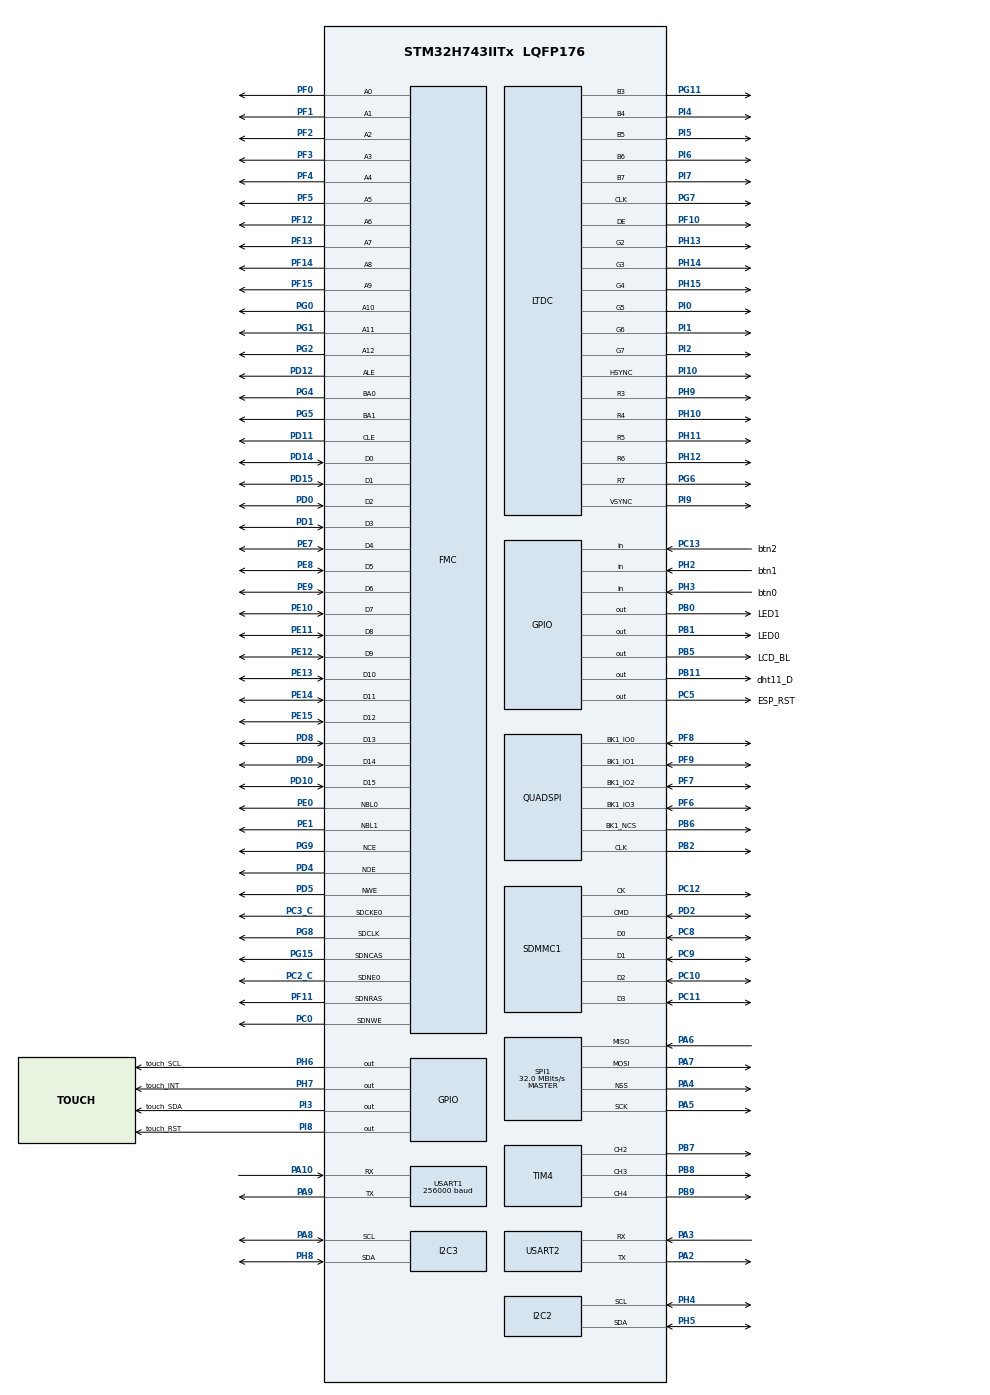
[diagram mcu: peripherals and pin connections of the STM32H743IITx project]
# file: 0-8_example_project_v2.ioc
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CORTEX_M7.CPU_DCache=Disabled
CORTEX_M7.CPU_ICache=Disabled
CORTEX_M7.MPU_Control=__NULL
CORTEX_M7.default_mode_Activation=0
DMA2D.ColorMode=DMA2D_OUTPUT_RGB565
Dma.I2C2_RX.4.Direction=DMA_PERIPH_TO_MEMORY
Dma.I2C2_RX.4.EventEnable=DISABLE
Dma.I2C2_RX.4.FIFOMode=DMA_FIFOMODE_DISABLE
Dma.I2C2_RX.4.Instance=DMA1_Stream4
Dma.I2C2_RX.4.MemDataAlignment=DMA_MDATAALIGN_BYTE
Dma.I2C2_RX.4.MemInc=DMA_MINC_ENABLE
Dma.I2C2_RX.4.Mode=DMA_NORMAL
Dma.I2C2_RX.4.PeriphDataAlignment=DMA_PDATAALIGN_BYTE
Dma.I2C2_RX.4.PeriphInc=DMA_PINC_DISABLE
Dma.I2C2_RX.4.Polarity=HAL_DMAMUX_REQ_GEN_RISING
Dma.I2C2_RX.4.Priority=DMA_PRIORITY_LOW
Dma.I2C2_RX.4.RequestNumber=1
Dma.I2C2_RX.4.SignalID=NONE
Dma.I2C2_RX.4.SyncEnable=DISABLE
Dma.I2C2_RX.4.SyncPolarity=HAL_DMAMUX_SYNC_NO_EVENT
Dma.I2C2_RX.4.SyncRequestNumber=1
Dma.I2C2_RX.4.SyncSignalID=NONE
Dma.I2C2_TX.5.Direction=DMA_MEMORY_TO_PERIPH
Dma.I2C2_TX.5.EventEnable=DISABLE
Dma.I2C2_TX.5.FIFOMode=DMA_FIFOMODE_DISABLE
Dma.I2C2_TX.5.Instance=DMA1_Stream5
Dma.I2C2_TX.5.MemDataAlignment=DMA_MDATAALIGN_BYTE
Dma.I2C2_TX.5.MemInc=DMA_MINC_ENABLE
Dma.I2C2_TX.5.Mode=DMA_NORMAL
Dma.I2C2_TX.5.PeriphDataAlignment=DMA_PDATAALIGN_BYTE
Dma.I2C2_TX.5.PeriphInc=DMA_PINC_DISABLE
Dma.I2C2_TX.5.Polarity=HAL_DMAMUX_REQ_GEN_RISING
Dma.I2C2_TX.5.Priority=DMA_PRIORITY_LOW
Dma.I2C2_TX.5.RequestNumber=1
Dma.I2C2_TX.5.SignalID=NONE
Dma.I2C2_TX.5.SyncEnable=DISABLE
Dma.I2C2_TX.5.SyncPolarity=HAL_DMAMUX_SYNC_NO_EVENT
Dma.I2C2_TX.5.SyncRequestNumber=1
Dma.I2C2_TX.5.SyncSignalID=NONE
Dma.I2C3_RX.6.Direction=DMA_PERIPH_TO_MEMORY
Dma.I2C3_RX.6.EventEnable=DISABLE
Dma.I2C3_RX.6.FIFOMode=DMA_FIFOMODE_DISABLE
Dma.I2C3_RX.6.Instance=DMA1_Stream6
Dma.I2C3_RX.6.MemDataAlignment=DMA_MDATAALIGN_BYTE
Dma.I2C3_RX.6.MemInc=DMA_MINC_ENABLE
Dma.I2C3_RX.6.Mode=DMA_NORMAL
Dma.I2C3_RX.6.PeriphDataAlignment=DMA_PDATAALIGN_BYTE
Dma.I2C3_RX.6.PeriphInc=DMA_PINC_DISABLE
Dma.I2C3_RX.6.Polarity=HAL_DMAMUX_REQ_GEN_RISING
Dma.I2C3_RX.6.Priority=DMA_PRIORITY_LOW
Dma.I2C3_RX.6.RequestNumber=1
Dma.I2C3_RX.6.SignalID=NONE
Dma.I2C3_RX.6.SyncEnable=DISABLE
Dma.I2C3_RX.6.SyncPolarity=HAL_DMAMUX_SYNC_NO_EVENT
Dma.I2C3_RX.6.SyncRequestNumber=1
Dma.I2C3_RX.6.SyncSignalID=NONE
Dma.I2C3_TX.7.Direction=DMA_MEMORY_TO_PERIPH
Dma.I2C3_TX.7.EventEnable=DISABLE
Dma.I2C3_TX.7.FIFOMode=DMA_FIFOMODE_DISABLE
Dma.I2C3_TX.7.Instance=DMA1_Stream7
Dma.I2C3_TX.7.MemDataAlignment=DMA_MDATAALIGN_BYTE
Dma.I2C3_TX.7.MemInc=DMA_MINC_ENABLE
Dma.I2C3_TX.7.Mode=DMA_NORMAL
Dma.I2C3_TX.7.PeriphDataAlignment=DMA_PDATAALIGN_BYTE
Dma.I2C3_TX.7.PeriphInc=DMA_PINC_DISABLE
Dma.I2C3_TX.7.Polarity=HAL_DMAMUX_REQ_GEN_RISING
Dma.I2C3_TX.7.Priority=DMA_PRIORITY_LOW
Dma.I2C3_TX.7.RequestNumber=1
Dma.I2C3_TX.7.SignalID=NONE
Dma.I2C3_TX.7.SyncEnable=DISABLE
Dma.I2C3_TX.7.SyncPolarity=HAL_DMAMUX_SYNC_NO_EVENT
Dma.I2C3_TX.7.SyncRequestNumber=1
Dma.I2C3_TX.7.SyncSignalID=NONE
Dma.Request0=USART1_RX
Dma.Request1=USART1_TX
Dma.Request2=USART2_RX
Dma.Request3=USART2_TX
Dma.Request4=I2C2_RX
Dma.Request5=I2C2_TX
Dma.Request6=I2C3_RX
Dma.Request7=I2C3_TX
Dma.USART1_RX.0.Direction=DMA_PERIPH_TO_MEMORY
Dma.USART1_RX.0.EventEnable=DISABLE
Dma.USART1_RX.0.FIFOMode=DMA_FIFOMODE_DISABLE
Dma.USART1_RX.0.Instance=DMA1_Stream0
Dma.USART1_RX.0.MemDataAlignment=DMA_MDATAALIGN_BYTE
Dma.USART1_RX.0.MemInc=DMA_MINC_ENABLE
Dma.USART1_RX.0.Mode=DMA_CIRCULAR
Dma.USART1_RX.0.PeriphDataAlignment=DMA_PDATAALIGN_BYTE
Dma.USART1_RX.0.PeriphInc=DMA_PINC_DISABLE
Dma.USART1_RX.0.Polarity=HAL_DMAMUX_REQ_GEN_RISING
Dma.USART1_RX.0.Priority=DMA_PRIORITY_LOW
Dma.USART1_RX.0.RequestNumber=1
Dma.USART1_RX.0.SignalID=NONE
Dma.USART1_RX.0.SyncEnable=DISABLE
Dma.USART1_RX.0.SyncPolarity=HAL_DMAMUX_SYNC_NO_EVENT
Dma.USART1_RX.0.SyncRequestNumber=1
Dma.USART1_RX.0.SyncSignalID=NONE
Dma.USART1_TX.1.Direction=DMA_MEMORY_TO_PERIPH
Dma.USART1_TX.1.EventEnable=DISABLE
Dma.USART1_TX.1.FIFOMode=DMA_FIFOMODE_DISABLE
Dma.USART1_TX.1.Instance=DMA1_Stream1
Dma.USART1_TX.1.MemDataAlignment=DMA_MDATAALIGN_BYTE
Dma.USART1_TX.1.MemInc=DMA_MINC_ENABLE
Dma.USART1_TX.1.Mode=DMA_NORMAL
Dma.USART1_TX.1.PeriphDataAlignment=DMA_PDATAALIGN_BYTE
Dma.USART1_TX.1.PeriphInc=DMA_PINC_DISABLE
Dma.USART1_TX.1.Polarity=HAL_DMAMUX_REQ_GEN_RISING
Dma.USART1_TX.1.Priority=DMA_PRIORITY_LOW
Dma.USART1_TX.1.RequestNumber=1
Dma.USART1_TX.1.SignalID=NONE
Dma.USART1_TX.1.SyncEnable=DISABLE
Dma.USART1_TX.1.SyncPolarity=HAL_DMAMUX_SYNC_NO_EVENT
Dma.USART1_TX.1.SyncRequestNumber=1
Dma.USART1_TX.1.SyncSignalID=NONE
Dma.USART2_RX.2.Direction=DMA_PERIPH_TO_MEMORY
Dma.USART2_RX.2.EventEnable=DISABLE
Dma.USART2_RX.2.FIFOMode=DMA_FIFOMODE_DISABLE
Dma.USART2_RX.2.Instance=DMA1_Stream2
Dma.USART2_RX.2.MemDataAlignment=DMA_MDATAALIGN_BYTE
Dma.USART2_RX.2.MemInc=DMA_MINC_ENABLE
Dma.USART2_RX.2.Mode=DMA_CIRCULAR
Dma.USART2_RX.2.PeriphDataAlignment=DMA_PDATAALIGN_BYTE
Dma.USART2_RX.2.PeriphInc=DMA_PINC_DISABLE
Dma.USART2_RX.2.Polarity=HAL_DMAMUX_REQ_GEN_RISING
Dma.USART2_RX.2.Priority=DMA_PRIORITY_LOW
Dma.USART2_RX.2.RequestNumber=1
Dma.USART2_RX.2.SignalID=NONE
Dma.USART2_RX.2.SyncEnable=DISABLE
Dma.USART2_RX.2.SyncPolarity=HAL_DMAMUX_SYNC_NO_EVENT
Dma.USART2_RX.2.SyncRequestNumber=1
Dma.USART2_RX.2.SyncSignalID=NONE
Dma.USART2_TX.3.Direction=DMA_MEMORY_TO_PERIPH
Dma.USART2_TX.3.EventEnable=DISABLE
Dma.USART2_TX.3.FIFOMode=DMA_FIFOMODE_DISABLE
Dma.USART2_TX.3.Instance=DMA1_Stream3
Dma.USART2_TX.3.MemDataAlignment=DMA_MDATAALIGN_BYTE
Dma.USART2_TX.3.MemInc=DMA_MINC_ENABLE
Dma.USART2_TX.3.Mode=DMA_NORMAL
Dma.USART2_TX.3.PeriphDataAlignment=DMA_PDATAALIGN_BYTE
Dma.USART2_TX.3.PeriphInc=DMA_PINC_DISABLE
Dma.USART2_TX.3.Polarity=HAL_DMAMUX_REQ_GEN_RISING
Dma.USART2_TX.3.Priority=DMA_PRIORITY_LOW
Dma.USART2_TX.3.RequestNumber=1
Dma.USART2_TX.3.SignalID=NONE
Dma.USART2_TX.3.SyncEnable=DISABLE
Dma.USART2_TX.3.SyncPolarity=HAL_DMAMUX_SYNC_NO_EVENT
Dma.USART2_TX.3.SyncRequestNumber=1
Dma.USART2_TX.3.SyncSignalID=NONE
FMC.AttributeSpaceHiZSetupTime1=3
FMC.AttributeSpaceHoldSetupTime1=3
FMC.AttributeSpaceSetupTime1=5
FMC.AttributeSpaceWaitSetupTime1=5
FMC.CASLatency1=FMC_SDRAM_CAS_LATENCY_2
FMC.ColumnBitsNumber1=FMC_SDRAM_COLUMN_BITS_NUM_9
FMC.CommonSpaceHiZSetupTime1=3
FMC.CommonSpaceHoldSetupTime1=3
FMC.CommonSpaceSetupTime1=5
FMC.CommonSpaceWaitSetupTime1=5
FMC.ECCPageSize1=FMC_NAND_ECC_PAGE_SIZE_512BYTE
FMC.EccComputation1=FMC_NAND_ECC_DISABLE
FMC.ExitSelfRefreshDelay1=8
FMC.LoadToActiveDelay1=2
FMC.NandBlockNbr1=4096
FMC.NandBlockSize1=64
FMC.NandExtraCommandEnable1=ENABLE
FMC.NandPageSize1=2048
FMC.NandPlaneNbr1=2
FMC.NandPlaneSize1=2048
FMC.NandSpareAreaSize1=64
FMC.RCDDelay1=2
FMC.RPDelay1=2
FMC.ReadBurst1=FMC_SDRAM_RBURST_ENABLE
FMC.ReadPipeDelay1=FMC_SDRAM_RPIPE_DELAY_1
FMC.RowCycleDelay1=6
FMC.SDClockPeriod1=FMC_SDRAM_CLOCK_PERIOD_2
FMC.SelfRefreshTime1=6
FMC.TARSetupTime1=4
FMC.TCLRSetupTime1=4
FMC.WriteRecoveryTime1=4
I2C2.Timing=0x307075B1
I2C3.Timing=0x307075B1
LTDC.ActiveW=800
LTDC.Alpha0_L0=0
LTDC.Alpha0_L1=0
LTDC.Alpha_L0=255
LTDC.Alpha_L1=255
LTDC.BlendingFactor1_L0=LTDC_BLENDING_FACTOR1_CA
LTDC.BlendingFactor1_L1=LTDC_BLENDING_FACTOR1_CA
LTDC.BlendingFactor2_L0=LTDC_BLENDING_FACTOR2_CA
LTDC.BlendingFactor2_L1=LTDC_BLENDING_FACTOR2_CA
LTDC.Blue=0
LTDC.Blue_L0=0
LTDC.Blue_L1=0
LTDC.FBStartAdress_L0=NULL
LTDC.FBStartAdress_L1=Layer1_Buffer
LTDC.Green=0
LTDC.Green_L0=0
LTDC.Green_L1=0
LTDC.HBP=88
LTDC.HFP=40
LTDC.HSync=48
LTDC.ImageHeight_L0=480
LTDC.ImageHeight_L1=480
LTDC.ImageWidth_L0=800
LTDC.Layers=0
LTDC.PCPolarity=LTDC_PCPOLARITY_IPC
LTDC.PixelFormat_L0=LTDC_PIXEL_FORMAT_RGB565
LTDC.Red=0
LTDC.Red_L0=0
LTDC.Red_L1=0
LTDC.VBP=32
LTDC.VFP=13
LTDC.VSync=3
LTDC.WindowX1_L0=800
LTDC.WindowX1_L1=800
LTDC.WindowY1_L0=480
LTDC.WindowY1_L1=480
Mcu.Family=STM32H7
Mcu.Name=STM32H743IITx
Mcu.Package=LQFP176
NVIC.DMA1_Stream0_IRQn=true\:0\:0\:false\:false\:true\:false\:true\:true
NVIC.DMA1_Stream1_IRQn=true\:0\:0\:false\:false\:true\:false\:true\:true
NVIC.DMA1_Stream2_IRQn=true\:0\:0\:false\:false\:true\:false\:true\:true
NVIC.DMA1_Stream3_IRQn=true\:0\:0\:false\:false\:true\:false\:true\:true
NVIC.DMA1_Stream4_IRQn=true\:0\:0\:false\:false\:true\:false\:true\:true
NVIC.DMA1_Stream5_IRQn=true\:0\:0\:false\:false\:true\:false\:true\:true
NVIC.DMA1_Stream6_IRQn=true\:0\:0\:false\:false\:true\:false\:true\:true
NVIC.DMA1_Stream7_IRQn=true\:0\:0\:false\:false\:true\:false\:true\:true
NVIC.DMA2D_IRQn=true\:1\:0\:true\:true\:true\:1\:true\:true\:true
NVIC.FMC_IRQn=true\:0\:0\:false\:false\:true\:true\:true\:true
NVIC.FPU_IRQn=true\:0\:0\:false\:false\:true\:true\:false\:true
NVIC.HSEM1_IRQn=true\:0\:0\:false\:false\:true\:true\:true\:true
NVIC.I2C2_ER_IRQn=true\:0\:0\:false\:false\:true\:true\:true\:true
NVIC.I2C2_EV_IRQn=true\:0\:0\:false\:false\:true\:true\:true\:true
NVIC.I2C3_ER_IRQn=true\:0\:0\:false\:false\:true\:true\:true\:true
NVIC.I2C3_EV_IRQn=true\:0\:0\:false\:false\:true\:true\:true\:true
NVIC.LTDC_ER_IRQn=true\:0\:0\:false\:false\:true\:true\:true\:true
NVIC.LTDC_IRQn=true\:0\:0\:false\:false\:true\:true\:true\:true
NVIC.PriorityGroup=NVIC_PRIORITYGROUP_4
NVIC.QUADSPI_IRQn=true\:0\:0\:false\:false\:true\:true\:true\:true
NVIC.SDMMC1_IRQn=true\:0\:0\:false\:false\:true\:true\:true\:true
NVIC.TIM6_DAC_IRQn=true\:0\:0\:false\:false\:true\:true\:true\:true
NVIC.USART1_IRQn=true\:2\:0\:true\:false\:true\:true\:true\:true
NVIC.USART2_IRQn=true\:1\:0\:true\:false\:true\:true\:true\:true
PA10.Mode=Asynchronous
PA10.Signal=USART1_RX
PA13\ (JTMS/SWDIO).Mode=Serial_Wire
PA13\ (JTMS/SWDIO).Signal=DEBUG_JTMS-SWDIO
PA14\ (JTCK/SWCLK).Mode=Serial_Wire
PA14\ (JTCK/SWCLK).Signal=DEBUG_JTCK-SWCLK
PA2.Mode=Asynchronous
PA2.Signal=USART2_TX
PA3.Mode=Asynchronous
PA3.Signal=USART2_RX
PA4.Mode=NSS_Signal_Hard_Output
PA4.Signal=SPI1_NSS
PA5.Mode=Full_Duplex_Master
PA5.Signal=SPI1_SCK
PA6.Mode=Full_Duplex_Master
PA6.Signal=SPI1_MISO
PA7.Mode=Full_Duplex_Master
PA7.Signal=SPI1_MOSI
PA8.Mode=I2C
PA8.Signal=I2C3_SCL
PA9.Mode=Asynchronous
PA9.Signal=USART1_TX
PB0.GPIO_Label=LED1
PB0.GPIO_PuPd=GPIO_NOPULL
PB0.GPIO_Speed=GPIO_SPEED_FREQ_HIGH
PB0.PinState=GPIO_PIN_RESET
PB0.Signal=GPIO_Output
PB1.GPIO_Label=LED0
PB1.GPIO_PuPd=GPIO_NOPULL
PB1.GPIO_Speed=GPIO_SPEED_FREQ_HIGH
PB1.PinState=GPIO_PIN_RESET
PB1.Signal=GPIO_Output
PB11.GPIO_Label=dht11_D
PB11.GPIO_Speed=GPIO_SPEED_FREQ_HIGH
PB11.Signal=GPIO_Output
PB2.GPIO_Speed=GPIO_SPEED_FREQ_VERY_HIGH
PB2.Mode=Single Bank 1
PB2.Signal=QUADSPI_CLK
PB5.GPIO_Label=LCD_BL
PB5.PinState=GPIO_PIN_SET
PB5.Signal=GPIO_Output
PB6.GPIO_FM6=__NULL
PB6.GPIO_PuPd=GPIO_PULLUP
PB6.GPIO_Speed=GPIO_SPEED_FREQ_VERY_HIGH
PB6.Mode=Single Bank 1
PB6.Signal=QUADSPI_BK1_NCS
PB7.Signal=S_TIM4_CH2
PB8.Signal=S_TIM4_CH3
PB9.Signal=S_TIM4_CH4
PC0.Signal=FMC_SDNWE
PC10.Mode=SD_4_bits_Wide_bus
PC10.Signal=SDMMC1_D2
PC11.Mode=SD_4_bits_Wide_bus
PC11.Signal=SDMMC1_D3
PC12.Mode=SD_4_bits_Wide_bus
PC12.Signal=SDMMC1_CK
PC13.GPIO_Label=btn2
PC13.GPIO_PuPd=GPIO_PULLUP
PC13.Signal=GPIO_Input
PC14-OSC32_IN\ (OSC32_IN).Mode=LSE-External-Oscillator
PC14-OSC32_IN\ (OSC32_IN).Signal=RCC_OSC32_IN
PC15-OSC32_OUT\ (OSC32_OUT).Mode=LSE-External-Oscillator
PC15-OSC32_OUT\ (OSC32_OUT).Signal=RCC_OSC32_OUT
PC2_C.Mode=SdramChipSelect1_1
PC2_C.Signal=FMC_SDNE0
PC3_C.Mode=SdramChipSelect1_1
PC3_C.Signal=FMC_SDCKE0
PC5.GPIO_Label=ESP_RST
PC5.Signal=GPIO_Output
PC8.Mode=SD_4_bits_Wide_bus
PC8.Signal=SDMMC1_D0
PC9.Mode=SD_4_bits_Wide_bus
PC9.Signal=SDMMC1_D1
PD0.Signal=FMC_D2_DA2
PD1.Signal=FMC_D3_DA3
PD10.Signal=FMC_D15_DA15
PD11.Signal=FMC_A16_CLE
PD12.Signal=FMC_A17_ALE
PD14.Signal=FMC_D0_DA0
PD15.Signal=FMC_D1_DA1
PD2.Mode=SD_4_bits_Wide_bus
PD2.Signal=SDMMC1_CMD
PD4.Signal=FMC_NOE
PD5.Signal=FMC_NWE
PD6.Signal=FMC_NWAIT
PD8.Signal=FMC_D13_DA13
PD9.Signal=FMC_D14_DA14
PE0.Signal=FMC_NBL0
PE1.Signal=FMC_NBL1
PE10.Signal=FMC_D7_DA7
PE11.Signal=FMC_D8_DA8
PE12.Signal=FMC_D9_DA9
PE13.Signal=FMC_D10_DA10
PE14.Signal=FMC_D11_DA11
PE15.Signal=FMC_D12_DA12
PE7.Signal=FMC_D4_DA4
PE8.Signal=FMC_D5_DA5
PE9.Signal=FMC_D6_DA6
PF0.Signal=FMC_A0
PF1.Signal=FMC_A1
PF10.GPIO_Speed=GPIO_SPEED_FREQ_VERY_HIGH
PF10.Mode=RGB565
PF10.Signal=LTDC_DE
PF11.Signal=FMC_SDNRAS
PF12.Signal=FMC_A6
PF13.Signal=FMC_A7
PF14.Signal=FMC_A8
PF15.Signal=FMC_A9
PF2.Signal=FMC_A2
PF3.Signal=FMC_A3
PF4.Signal=FMC_A4
PF5.Signal=FMC_A5
PF6.GPIO_Speed=GPIO_SPEED_FREQ_VERY_HIGH
PF6.Mode=Single Bank 1
PF6.Signal=QUADSPI_BK1_IO3
PF7.GPIO_Speed=GPIO_SPEED_FREQ_VERY_HIGH
PF7.Mode=Single Bank 1
PF7.Signal=QUADSPI_BK1_IO2
PF8.GPIO_Speed=GPIO_SPEED_FREQ_VERY_HIGH
PF8.Mode=Single Bank 1
PF8.Signal=QUADSPI_BK1_IO0
PF9.GPIO_Speed=GPIO_SPEED_FREQ_VERY_HIGH
PF9.Mode=Single Bank 1
PF9.Signal=QUADSPI_BK1_IO1
PG0.Signal=FMC_A10
PG1.Signal=FMC_A11
PG11.GPIO_Speed=GPIO_SPEED_FREQ_VERY_HIGH
PG11.Mode=RGB565
PG11.Signal=LTDC_B3
PG15.Signal=FMC_SDNCAS
PG2.Signal=FMC_A12
PG4.Signal=FMC_A14_BA0
PG5.Signal=FMC_A15_BA1
PG6.GPIO_Speed=GPIO_SPEED_FREQ_VERY_HIGH
PG6.Mode=RGB565
PG6.Signal=LTDC_R7
PG7.GPIO_Speed=GPIO_SPEED_FREQ_VERY_HIGH
PG7.Mode=RGB565
PG7.Signal=LTDC_CLK
PG8.Signal=FMC_SDCLK
PG9.Mode=NandChipSelect3_1
PG9.Signal=FMC_NCE
PH0-OSC_IN\ (PH0).Mode=HSE-External-Oscillator
PH0-OSC_IN\ (PH0).Signal=RCC_OSC_IN
PH1-OSC_OUT\ (PH1).Mode=HSE-External-Oscillator
PH1-OSC_OUT\ (PH1).Signal=RCC_OSC_OUT
PH10.GPIO_Speed=GPIO_SPEED_FREQ_VERY_HIGH
PH10.Mode=RGB565
PH10.Signal=LTDC_R4
PH11.GPIO_Speed=GPIO_SPEED_FREQ_VERY_HIGH
PH11.Mode=RGB565
PH11.Signal=LTDC_R5
PH12.GPIO_Speed=GPIO_SPEED_FREQ_VERY_HIGH
PH12.Mode=RGB565
PH12.Signal=LTDC_R6
PH13.GPIO_Speed=GPIO_SPEED_FREQ_VERY_HIGH
PH13.Mode=RGB565
PH13.Signal=LTDC_G2
PH14.GPIO_Speed=GPIO_SPEED_FREQ_VERY_HIGH
PH14.Mode=RGB565
PH14.Signal=LTDC_G3
PH15.GPIO_Speed=GPIO_SPEED_FREQ_VERY_HIGH
PH15.Mode=RGB565
PH15.Signal=LTDC_G4
PH2.GPIO_Label=btn1
PH2.GPIO_PuPd=GPIO_PULLUP
PH2.Signal=GPIO_Input
PH3.GPIO_Label=btn0
PH3.GPIO_PuPd=GPIO_PULLUP
PH3.Signal=GPIO_Input
PH4.GPIO_Speed=GPIO_SPEED_FREQ_VERY_HIGH
PH4.Mode=I2C
PH4.Signal=I2C2_SCL
PH5.GPIO_Speed=GPIO_SPEED_FREQ_VERY_HIGH
PH5.Mode=I2C
PH5.Signal=I2C2_SDA
PH6.GPIO_Label=touch_SCL
PH6.GPIO_ModeDefaultOutputPP=GPIO_MODE_OUTPUT_PP
PH6.GPIO_PuPd=GPIO_PULLUP
PH6.GPIO_Speed=GPIO_SPEED_FREQ_HIGH
PH6.PinState=GPIO_PIN_RESET
PH6.Signal=GPIO_Output
PH7.GPIO_Label=touch_INT
PH7.GPIO_Speed=GPIO_SPEED_FREQ_HIGH
PH7.Signal=GPIO_Output
PH8.Mode=I2C
PH8.Signal=I2C3_SDA
PH9.GPIO_Speed=GPIO_SPEED_FREQ_VERY_HIGH
PH9.Mode=RGB565
PH9.Signal=LTDC_R3
PI0.GPIO_Speed=GPIO_SPEED_FREQ_VERY_HIGH
PI0.Mode=RGB565
PI0.Signal=LTDC_G5
PI1.GPIO_Speed=GPIO_SPEED_FREQ_VERY_HIGH
PI1.Mode=RGB565
PI1.Signal=LTDC_G6
PI10.GPIO_Speed=GPIO_SPEED_FREQ_VERY_HIGH
PI10.Mode=RGB565
PI10.Signal=LTDC_HSYNC
PI2.GPIO_Speed=GPIO_SPEED_FREQ_VERY_HIGH
PI2.Mode=RGB565
PI2.Signal=LTDC_G7
PI3.GPIO_Label=touch_SDA
PI3.GPIO_PuPd=GPIO_PULLUP
PI3.GPIO_Speed=GPIO_SPEED_FREQ_HIGH
PI3.PinState=GPIO_PIN_RESET
PI3.Signal=GPIO_Output
PI4.GPIO_Speed=GPIO_SPEED_FREQ_VERY_HIGH
PI4.Mode=RGB565
PI4.Signal=LTDC_B4
PI5.GPIO_Speed=GPIO_SPEED_FREQ_VERY_HIGH
PI5.Mode=RGB565
PI5.Signal=LTDC_B5
PI6.GPIO_Speed=GPIO_SPEED_FREQ_VERY_HIGH
PI6.Mode=RGB565
PI6.Signal=LTDC_B6
PI7.GPIO_Speed=GPIO_SPEED_FREQ_VERY_HIGH
PI7.Mode=RGB565
PI7.Signal=LTDC_B7
PI8.GPIO_Label=touch_RST
PI8.Signal=GPIO_Output
PI9.GPIO_Speed=GPIO_SPEED_FREQ_VERY_HIGH
PI9.Mode=RGB565
PI9.Signal=LTDC_VSYNC
ProjectManager.HeapSize=0x2048
ProjectManager.StackSize=0x2048
ProjectManager.TargetToolchain=STM32CubeIDE
QUADSPI.ChipSelectHighTime=QSPI_CS_HIGH_TIME_3_CYCLE
QUADSPI.ClockMode=QSPI_CLOCK_MODE_3
QUADSPI.ClockPrescaler=1
QUADSPI.FifoThreshold=4
QUADSPI.FlashSize=POSITION_VAL(0x2000000)-1
QUADSPI.SampleShifting=QSPI_SAMPLE_SHIFTING_HALFCYCLE
RCC.ADCFreq_Value=200000000
RCC.APB1Freq_Value=120000000
RCC.APB2Freq_Value=120000000
RCC.APB3Freq_Value=120000000
RCC.APB4Freq_Value=120000000
RCC.CortexFreq_Value=480000000
RCC.D1PPRE=RCC_APB3_DIV2
RCC.D2PPRE1=RCC_APB1_DIV2
RCC.D2PPRE2=RCC_APB2_DIV2
RCC.D3PPRE=RCC_APB4_DIV2
RCC.DIVM1=5
RCC.DIVM2=5
RCC.DIVM3=25
RCC.DIVN1=192
RCC.DIVN2=160
RCC.DIVN3=396
RCC.DIVP2=4
RCC.DIVQ1=4
RCC.DIVQ2=8
RCC.DIVR1=4
RCC.DIVR2=4
RCC.DIVR3=12
RCC.HCLKFreq_Value=240000000
RCC.HPRE=RCC_HCLK_DIV2
RCC.PLL1_VCI_Range-AdvancedSettings=RCC_PLL1VCIRANGE_0
RCC.PLL2FRACN=0
RCC.PLL3FRACN=0
RCC.PLLFRACN=0
RCC.PLLSourceVirtual=RCC_PLLSOURCE_HSE
RCC.QSPICLockSelection=RCC_QSPICLKSOURCE_PLL2
RCC.RTCClockSelection=RCC_RTCCLKSOURCE_LSE
RCC.SDMMC1CLockSelection=RCC_SDMMCCLKSOURCE_PLL2
RCC.SPI123CLockSelection=RCC_SPI123CLKSOURCE_CLKP
RCC.SYSCLKFreq_VALUE=480000000
RCC.SYSCLKSource=RCC_SYSCLKSOURCE_PLLCLK
RCC.USBFreq_Value=240000000
RTC.Date=25
RTC.Format=RTC_FORMAT_BCD
RTC.Hours=22
RTC.Minutes=22
RTC.Month=RTC_MONTH_OCTOBER
RTC.Seconds=22
RTC.Year=25
SDMMC1.ClockDiv=SDMMC_NSpeed_CLK_DIV
SH.FMC_A0.0=FMC_A0,13b-sda1
SH.FMC_A1.0=FMC_A1,13b-sda1
SH.FMC_A10.0=FMC_A10,13b-sda1
SH.FMC_A11.0=FMC_A11,13b-sda1
SH.FMC_A12.0=FMC_A12,13b-sda1
SH.FMC_A14_BA0.0=FMC_BA0,FourSdramBanks1
SH.FMC_A15_BA1.0=FMC_BA1,FourSdramBanks1
SH.FMC_A16_CLE.0=FMC_CLE,8b-dmux1
SH.FMC_A17_ALE.0=FMC_ALE,8b-dmux1
SH.FMC_A2.0=FMC_A2,13b-sda1
SH.FMC_A3.0=FMC_A3,13b-sda1
SH.FMC_A4.0=FMC_A4,13b-sda1
SH.FMC_A5.0=FMC_A5,13b-sda1
SH.FMC_A6.0=FMC_A6,13b-sda1
SH.FMC_A7.0=FMC_A7,13b-sda1
SH.FMC_A8.0=FMC_A8,13b-sda1
SH.FMC_A9.0=FMC_A9,13b-sda1
SH.FMC_D0_DA0.0=FMC_D0,sd-16b-d1
SH.FMC_D0_DA0.1=FMC_D0,8b-dmux1
SH.FMC_D10_DA10.0=FMC_D10,sd-16b-d1
SH.FMC_D11_DA11.0=FMC_D11,sd-16b-d1
SH.FMC_D12_DA12.0=FMC_D12,sd-16b-d1
SH.FMC_D13_DA13.0=FMC_D13,sd-16b-d1
SH.FMC_D14_DA14.0=FMC_D14,sd-16b-d1
SH.FMC_D15_DA15.0=FMC_D15,sd-16b-d1
SH.FMC_D1_DA1.0=FMC_D1,sd-16b-d1
SH.FMC_D1_DA1.1=FMC_D1,8b-dmux1
SH.FMC_D2_DA2.0=FMC_D2,sd-16b-d1
SH.FMC_D2_DA2.1=FMC_D2,8b-dmux1
SH.FMC_D3_DA3.0=FMC_D3,sd-16b-d1
SH.FMC_D3_DA3.1=FMC_D3,8b-dmux1
SH.FMC_D4_DA4.0=FMC_D4,sd-16b-d1
SH.FMC_D4_DA4.1=FMC_D4,8b-dmux1
SH.FMC_D5_DA5.0=FMC_D5,sd-16b-d1
SH.FMC_D5_DA5.1=FMC_D5,8b-dmux1
SH.FMC_D6_DA6.0=FMC_D6,sd-16b-d1
SH.FMC_D6_DA6.1=FMC_D6,8b-dmux1
SH.FMC_D7_DA7.0=FMC_D7,sd-16b-d1
SH.FMC_D7_DA7.1=FMC_D7,8b-dmux1
SH.FMC_D8_DA8.0=FMC_D8,sd-16b-d1
SH.FMC_D9_DA9.0=FMC_D9,sd-16b-d1
SH.FMC_NBL0.0=FMC_NBL0,Sd2ByteEnable1
SH.FMC_NBL1.0=FMC_NBL1,Sd2ByteEnable1
SH.FMC_NOE.0=FMC_NOE,8b-dmux1
SH.FMC_NWAIT.0=FMC_NWAIT
SH.FMC_NWE.0=FMC_NWE,8b-dmux1
SH.FMC_SDCLK.0=FMC_SDCLK,13b-sda1
SH.FMC_SDNCAS.0=FMC_SDNCAS,13b-sda1
SH.FMC_SDNRAS.0=FMC_SDNRAS,13b-sda1
SH.FMC_SDNWE.0=FMC_SDNWE,13b-sda1
SH.S_TIM4_CH2.0=TIM4_CH2,PWM Generation2 CH2
SH.S_TIM4_CH3.0=TIM4_CH3,PWM Generation3 CH3
SH.S_TIM4_CH4.0=TIM4_CH4,PWM Generation4 CH4
SPI1.CalculateBaudRate=32.0 MBits/s
SPI1.Direction=SPI_DIRECTION_2LINES
SPI1.Mode=SPI_MODE_MASTER
SPI1.VirtualNSS=VM_NSSHARD
SPI1.VirtualType=VM_MASTER
TIM4.Channel-PWM\ Generation2\ CH2=TIM_CHANNEL_2
TIM4.Channel-PWM\ Generation3\ CH3=TIM_CHANNEL_3
TIM4.Channel-PWM\ Generation4\ CH4=TIM_CHANNEL_4
TIM6.AutoReloadPreload=TIM_AUTORELOAD_PRELOAD_ENABLE
TIM6.Period=100-1
TIM6.Prescaler=2400-1
USART1.BaudRate=256000
USART1.VirtualMode-Asynchronous=VM_ASYNC
USART2.VirtualMode-Asynchronous=VM_ASYNC
VP_CRC_VS_CRC.Mode=CRC_Activate
VP_DMA2D_VS_DMA2D.Mode=DMA2D_Activate
VP_MEMORYMAP_VS_MEMORYMAP.Mode=CurAppReg
VP_RTC_VS_RTC_Activate.Mode=RTC_Enabled
VP_RTC_VS_RTC_Calendar.Mode=RTC_Calendar
VP_TIM6_VS_ClockSourceINT.Mode=Enable_Timer
board=custom

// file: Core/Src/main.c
/* USER CODE BEGIN Header */
/**
 ******************************************************************************
 * @file           : main.c
 * @brief          : Main program body
 ******************************************************************************
 * @attention
 *
 * Copyright (c) 2026 STMicroelectronics.
 * All rights reserved.
 *
 * This software is licensed under terms that can be found in the LICENSE file
 * in the root directory of this software component.
 * If no LICENSE file comes with this software, it is provided AS-IS.
 *
 ******************************************************************************
 */
/* USER CODE END Header */
#include "main.h"
#include "crc.h"
#include "dma.h"
#include "dma2d.h"
#include "i2c.h"
#include "ltdc.h"
#include "quadspi.h"
#include "rtc.h"
#include "sdmmc.h"
#include "spi.h"
#include "tim.h"
#include "usart.h"
#include "gpio.h"
#include "fmc.h"

/* USER CODE BEGIN Includes */
#include "BSP_init.h"
#include "app.h"
#include "shell_port.h"
#include "test_framework.h"
/* USER CODE END Includes */

void SystemClock_Config(void);
void PeriphCommonClock_Config(void);
static void MX_NVIC_Init(void);

int main(void)
{

  /* MCU Configuration--------------------------------------------------------*/

  /* Reset of all peripherals, Initializes the Flash interface and the Systick. */
  HAL_Init();

  /* Configure the system clock */
  SystemClock_Config();

  /* Configure the peripherals common clocks */
  PeriphCommonClock_Config();

  /* Initialize all configured peripherals */
  MX_GPIO_Init();
  MX_DMA_Init();
  MX_USART1_UART_Init();
  MX_FMC_Init();
  MX_LTDC_Init();
  MX_DMA2D_Init();
  MX_TIM6_Init();
  MX_RTC_Init();
  MX_USART2_UART_Init();
  MX_SPI1_Init();
  MX_QUADSPI_Init();
  MX_SDMMC1_SD_Init();
  MX_I2C2_Init();
  MX_I2C3_Init();
  MX_CRC_Init();
  MX_TIM4_Init();

  /* Initialize interrupts */
  MX_NVIC_Init();
  /* USER CODE BEGIN 2 */
  GPIOB->ODR ^= (1 << 0);
  GPIOB->ODR ^= (1 << 1);
  HAL_Delay(800);

  bsp_init(); // 驱动层初始化
  app_init();
#if SHELL_ENABLE
  userShellInit();
#endif
  Test_Framework_Init();

  /* USER CODE END 2 */

  /* Infinite loop */
  /* USER CODE BEGIN WHILE */
  while (1) {
#if SHELL_ENABLE
	userShellProcess();
#endif
    Test_Framework_Run();
    bsp_process();
    app_run();

    /* USER CODE END WHILE */

  }
}

void SystemClock_Config(void)
{
  RCC_OscInitTypeDef RCC_OscInitStruct = {0};
  RCC_ClkInitTypeDef RCC_ClkInitStruct = {0};

  /** Supply configuration update enable
  */
  HAL_PWREx_ConfigSupply(PWR_LDO_SUPPLY);

  /** Configure the main internal regulator output voltage
  */
  __HAL_PWR_VOLTAGESCALING_CONFIG(PWR_REGULATOR_VOLTAGE_SCALE0);

  while(!__HAL_PWR_GET_FLAG(PWR_FLAG_VOSRDY)) {}

  /** Configure LSE Drive Capability
  */
  HAL_PWR_EnableBkUpAccess();
  __HAL_RCC_LSEDRIVE_CONFIG(RCC_LSEDRIVE_LOW);

  /** Initializes the RCC Oscillators according to the specified parameters
  * in the RCC_OscInitTypeDef structure.
  */
  RCC_OscInitStruct.OscillatorType = RCC_OSCILLATORTYPE_HSI|RCC_OSCILLATORTYPE_HSE
                              |RCC_OSCILLATORTYPE_LSE;
  RCC_OscInitStruct.HSEState = RCC_HSE_ON;
  RCC_OscInitStruct.LSEState = RCC_LSE_ON;
  RCC_OscInitStruct.HSIState = RCC_HSI_DIV1;
  RCC_OscInitStruct.HSICalibrationValue = RCC_HSICALIBRATION_DEFAULT;
  RCC_OscInitStruct.PLL.PLLState = RCC_PLL_ON;
  RCC_OscInitStruct.PLL.PLLSource = RCC_PLLSOURCE_HSE;
  RCC_OscInitStruct.PLL.PLLM = 5;
  RCC_OscInitStruct.PLL.PLLN = 192;
  RCC_OscInitStruct.PLL.PLLP = 2;
  RCC_OscInitStruct.PLL.PLLQ = 4;
  RCC_OscInitStruct.PLL.PLLR = 4;
  RCC_OscInitStruct.PLL.PLLRGE = RCC_PLL1VCIRANGE_2;
  RCC_OscInitStruct.PLL.PLLVCOSEL = RCC_PLL1VCOWIDE;
  RCC_OscInitStruct.PLL.PLLFRACN = 0;
  if (HAL_RCC_OscConfig(&RCC_OscInitStruct) != HAL_OK)
  {
    Error_Handler();
  }

  /** Initializes the CPU, AHB and APB buses clocks
  */
  RCC_ClkInitStruct.ClockType = RCC_CLOCKTYPE_HCLK|RCC_CLOCKTYPE_SYSCLK
                              |RCC_CLOCKTYPE_PCLK1|RCC_CLOCKTYPE_PCLK2
                              |RCC_CLOCKTYPE_D3PCLK1|RCC_CLOCKTYPE_D1PCLK1;
  RCC_ClkInitStruct.SYSCLKSource = RCC_SYSCLKSOURCE_PLLCLK;
  RCC_ClkInitStruct.SYSCLKDivider = RCC_SYSCLK_DIV1;
  RCC_ClkInitStruct.AHBCLKDivider = RCC_HCLK_DIV2;
  RCC_ClkInitStruct.APB3CLKDivider = RCC_APB3_DIV2;
  RCC_ClkInitStruct.APB1CLKDivider = RCC_APB1_DIV2;
  RCC_ClkInitStruct.APB2CLKDivider = RCC_APB2_DIV2;
  RCC_ClkInitStruct.APB4CLKDivider = RCC_APB4_DIV2;

  if (HAL_RCC_ClockConfig(&RCC_ClkInitStruct, FLASH_LATENCY_4) != HAL_OK)
  {
    Error_Handler();
  }
}

void PeriphCommonClock_Config(void)
{
  RCC_PeriphCLKInitTypeDef PeriphClkInitStruct = {0};

  /** Initializes the peripherals clock
  */
  PeriphClkInitStruct.PeriphClockSelection = RCC_PERIPHCLK_QSPI|RCC_PERIPHCLK_SDMMC
                              |RCC_PERIPHCLK_CKPER;
  PeriphClkInitStruct.PLL2.PLL2M = 5;
  PeriphClkInitStruct.PLL2.PLL2N = 160;
  PeriphClkInitStruct.PLL2.PLL2P = 4;
  PeriphClkInitStruct.PLL2.PLL2Q = 8;
  PeriphClkInitStruct.PLL2.PLL2R = 4;
  PeriphClkInitStruct.PLL2.PLL2RGE = RCC_PLL2VCIRANGE_2;
  PeriphClkInitStruct.PLL2.PLL2VCOSEL = RCC_PLL2VCOWIDE;
  PeriphClkInitStruct.PLL2.PLL2FRACN = 0;
  PeriphClkInitStruct.QspiClockSelection = RCC_QSPICLKSOURCE_PLL2;
  PeriphClkInitStruct.SdmmcClockSelection = RCC_SDMMCCLKSOURCE_PLL2;
  PeriphClkInitStruct.CkperClockSelection = RCC_CLKPSOURCE_HSI;
  if (HAL_RCCEx_PeriphCLKConfig(&PeriphClkInitStruct) != HAL_OK)
  {
    Error_Handler();
  }
}

/**
  * @brief NVIC Configuration.
  * @retval None
  */
static void MX_NVIC_Init(void)
{
  /* DMA2D_IRQn interrupt configuration */
  HAL_NVIC_SetPriority(DMA2D_IRQn, 1, 0);
  HAL_NVIC_EnableIRQ(DMA2D_IRQn);
}

void Error_Handler(void)
{
  /* USER CODE BEGIN Error_Handler_Debug */
  /* User can add his own implementation to report the HAL error return state */
  __disable_irq();
  GPIOB->ODR ^= (1 << 0);
  GPIOB->ODR ^= (1 << 1);
  while (1) {
    GPIOB->ODR ^= (1 << 0); // PB0
    for (__IO int i = 0; i < 10000; i++) {
      for (__IO int j = 0; j < 1000; j++) {
      }
    }
  }
  /* USER CODE END Error_Handler_Debug */
}
#ifdef USE_FULL_ASSERT
/**
  * @brief  Reports the name of the source file and the source line number
  *         where the assert_param error has occurred.
  * @param  file: pointer to the source file name
  * @param  line: assert_param error line source number
  * @retval None
  */
void assert_failed(uint8_t *file, uint32_t line)
{
  /* USER CODE BEGIN 6 */
  /* User can add his own implementation to report the file name and line
     number, ex: printf("Wrong parameters value: file %s on line %d\r\n", file,
     line) */
  /* USER CODE END 6 */
}
#endif /* USE_FULL_ASSERT */
